# AM13E23019 register map
Vendor: Texas Instruments; File version: 1.0
CPU: CM33 r0p1, little endian, MPU, FPU, VTOR, 4 interrupt priority bits
Registers are 32-bit, read-write, reset 0x0 unless marked. A register's access mark holds for its fields unless they carry their own. Offsets are from the block's base; [hi:lo] are bit positions; {n}, {i} and the like mark numbered series.

## IOMUX — IOMUX module
Base 0x400CC000
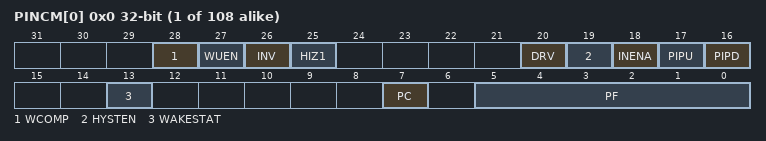
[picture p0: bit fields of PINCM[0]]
{0x0+4i} PINCM[{i}] (i=0..107) access per field — Pin Control Management Register in SECCFG region
  [28] WCOMP rw — Wakeup Compare Value bit
    0=MATCH0 (Wakeup on a match of 0); 1=MATCH1 (Wakeup on a match of 1)
  [27] WUEN rw — Wakeup Enable bit
    0=DISABLE (wakeup is disabled.); 1=ENABLE (wakeup is enabled)
  [26] INV rw — Data inversion selection
    0=DISABLE (Data inversion is disabled.); 1=ENABLE (Data inversion is enabled)
  [25] HIZ1 rw — High output value will tri-state the output when this bit is enabled
    0=DISABLE (open-drain is disabled.); 1=ENABLE (open-drain is enabled.)
  [20] DRV rw — Drive strength control selection, for HS IOCELL only
    0=DRVVAL0 (Drive setting of 0 selected); 1=DRVVAL1 (Drive setting of 1 selected)
  [19] HYSTEN rw — Hystersis Enable Control Selection
    0=DISABLE (hysteresis is disabled.); 1=ENABLE (hysteresis is enabled)
  [18] INENA rw — Input Enable Control Selection
    0=DISABLE (Input enable is disabled.); 1=ENABLE (Input enable is enabled.)
  [17] PIPU rw — Pull Up control selection
    0=DISABLE (Pull up is disabled.); 1=ENABLE (Pull up is enabled)
  [16] PIPD rw — Pull Down control selection
    0=DISABLE (Pull down is disabled.); 1=ENABLE (Pull down is enabled)
  [13] WAKESTAT ro — This has the IOPAD WAKEUP signal as status bit.
    0=DISABLE (wakeup source is NOT from this IOCELL); 1=ENABLE (wakeup source is from this IOCELL)
  [7] PC rw — Peripheral is Connected
    0=UNCONNECTED (The output of the peripheral (and its output enable) will not propagate to the IOCELL); 1=CONNECTED (The output latch of the dataflow will be transparent)
  [5:0] PF rw — P channel Function selection bits
    0=MINIMUM (Reserved as unconnected); 63=MAXIMUM (An encoding per function that can be connected to this pin.)

## PGA0 — PGA module
Base 0x400FC000
Same registers: PGA1 0x400FD000, PGA2 0x400FE000
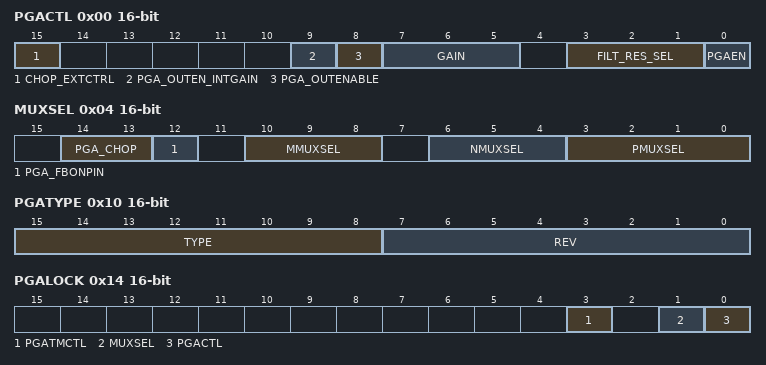
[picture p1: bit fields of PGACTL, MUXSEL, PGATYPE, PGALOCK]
0x00 PGACTL 16-bit — PGA Control Register
  [15] CHOP_EXTCTRL — External Chop Signal Control
  [9] PGA_OUTEN_INTGAIN — PGA Internal Gain Output Enable
  [8] PGA_OUTENABLE — PGA Output Enable
  [7:5] GAIN — PGA gain setting
  [3:1] FILT_RES_SEL — Filter Resistor Select
  [0] PGAEN — PGA Enable
0x04 MUXSEL 16-bit — Mux Selection Register
  [14:13] PGA_CHOP — Chopper Mode Control
  [12] PGA_FBONPIN — Connect PGAOUT to PGA_INM
  [10:8] MMUXSEL — M Mux Select
  [6:4] NMUXSEL — Negative Input Mux Select
  [3:0] PMUXSEL — Positive Input Mux Select
0x10 PGATYPE 16-bit ro
  [15:8] TYPE — PGA Type Field
  [7:0] REV — PGA Revision Field
0x14 PGALOCK 16-bit
  [3] PGATMCTL — Lock but for PGATMCTL
  [1] MUXSEL — Lock bit for MUXSEL
  [0] PGACTL — Lock bit for PGACTL.

## KEYSTORE — KEYSTORECTL module
Base 0x401B6000
0x1100 CFG — Keystore configuration
  [3:0] NK256 — Number of 256 bit keys to be held in the key-store. Can not exceed the total number of slots present in the hardware / 2. For eg: if SYS_N_SLOTS = 4, then atmost 2 256-bit keys can be held in the key-store. Incorrect setting of this field will be reported via STATUS register
    0=ZERO (No 256-bit keys); 1=ONE (One 256-bit key); 2=TWO (Two 256-bit keys); 3=THREE (Three 256-bit keys); 4=FOUR (Four 256-bit keys)
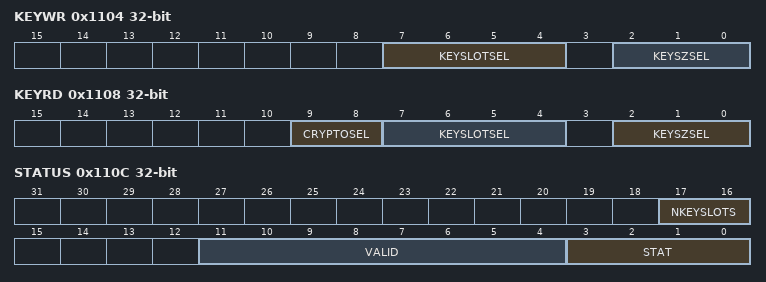
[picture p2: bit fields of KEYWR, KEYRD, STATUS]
0x1104 KEYWR — Key write configuration
  [7:4] KEYSLOTSEL — Select the key slot to write the key into. NOTE: SW needs to ensure that it is writing to the correct slots. The slot numbering is from 0 through SYS_N_SLOTS-1. Each slot is a 128-bit slot. Therefore, when writing a 256-bit key, two slots will need to budgeted. The selected slot for the 256-bit key needs to be an even numbered slot (eg: 0 or 2). Also all the 256-bit keys need to be stored in lower numbered slots and 128-bit keys stored in higher numbered slots.
    {v}=SLOT{v} (v=0..7)
  [2:0] KEYSZSEL — Key size selection. Selection of 128 or 256 bit keys
    0=K256 (256 bit key); 1=K128 (128 bit key)
0x1108 KEYRD — Key read configuration
  [9:8] CRYPTOSEL — Crypto engine selector
    0=AES (Transfer key to AES)
  [7:4] KEYSLOTSEL — Select the key slot to read the key from. NOTE: SW needs to ensure that it is reading from the correct slots. The slot numbering is from 0 through SYS_N_SLOTS-1. Each slot is a 128-bit slot. Therefore, when reading a 256-bit key, two adjacent slots will be read. For a 256-bit key, an even numbered slot index must be specified.
  [2:0] KEYSZSEL — Key size selection. Selection of 128 or 256 bit keys
    0=K256 (256 bit key); 1=K128 (128 bit key)
0x110C STATUS access per field
  [17:16] NKEYSLOTS ro — Size of keystorage: Number of 128-bit key slots
    0=TWO (Two slots); 1=THREE (Three slots); 2=FOUR (Four slots)
  [11:4] VALID rw — Bitvector of valid bits to indicate which slots have been configured
  [3:0] STAT rw — Status information
    0=VALID (Valid configuration); 1=NO_CFG (Key-store has not been configured. NK256 has not been set.); 2=INVALID_NK256 (Invalid value for NK256 field in CFG.); 3=BUSY_RECEIVE (Busy receiving a key deposit); 4=BUSY_TRANSMIT (Busy transmitting a key to a crypto engine); 5=INVALID_KEYSLOTSELW (Invalid keyslot selection for writing); 6=INVALID_KEYSLOTSELR (Invalid keyslot selection for reading)
0x1110 KEYIN access not given — Input key
0x1114 KEYLOCK
  [7:0] LOCKBIT — Bitvector of lock bits to lock certain slots from being used by application.
